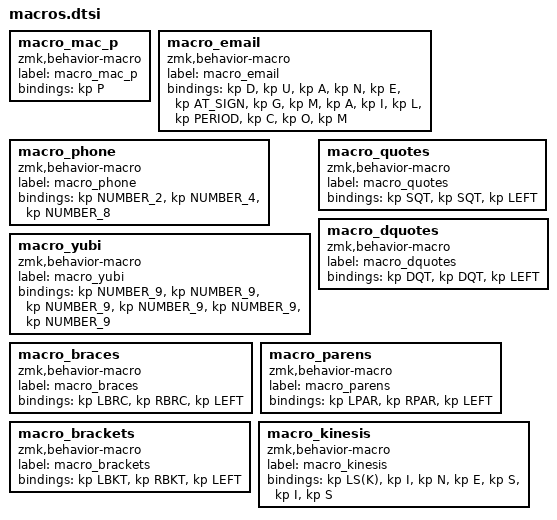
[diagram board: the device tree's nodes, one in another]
macro_mac_p: macro_mac_p{
compatible = "zmk,behavior-macro";
label = "macro_mac_p";
#binding-cells = <0>;
bindings = <&kp P>;
};
macro_email: macro_email{
compatible = "zmk,behavior-macro";
label = "macro_email";
#binding-cells = <0>;
bindings = <&kp D>, <&kp U>, <&kp A>, <&kp N>, <&kp E>, <&kp AT_SIGN>, <&kp G>, <&kp M>, <&kp A>, <&kp I>, <&kp L>, <&kp PERIOD>, <&kp C>, <&kp O>, <&kp M>;
};
macro_phone: macro_phone{
compatible = "zmk,behavior-macro";
label = "macro_phone";
#binding-cells = <0>;
bindings = <&kp NUMBER_2>, <&kp NUMBER_4>, <&kp NUMBER_8>;
};
macro_yubi: macro_yubi{
compatible = "zmk,behavior-macro";
label = "macro_yubi";
#binding-cells = <0>;
bindings = <&kp NUMBER_9>, <&kp NUMBER_9>, <&kp NUMBER_9>, <&kp NUMBER_9>, <&kp NUMBER_9>, <&kp NUMBER_9>;
};
macro_quotes: macro_quotes{
compatible = "zmk,behavior-macro";
label = "macro_quotes";
#binding-cells = <0>;
bindings = <&kp SQT>, <&kp SQT>, <&kp LEFT>;
};
macro_dquotes: macro_dquotes{
compatible = "zmk,behavior-macro";
label = "macro_dquotes";
#binding-cells = <0>;
bindings = <&kp DQT>, <&kp DQT>, <&kp LEFT>;
};
macro_braces: macro_braces{
compatible = "zmk,behavior-macro";
label = "macro_braces";
#binding-cells = <0>;
bindings = <&kp LBRC>, <&kp RBRC>, <&kp LEFT>;
};
macro_parens: macro_parens{
compatible = "zmk,behavior-macro";
label = "macro_parens";
#binding-cells = <0>;
bindings = <&kp LPAR>, <&kp RPAR>, <&kp LEFT>;
};
macro_brackets: macro_brackets{
compatible = "zmk,behavior-macro";
label = "macro_brackets";
#binding-cells = <0>;
bindings = <&kp LBKT>, <&kp RBKT>, <&kp LEFT>;
};
macro_kinesis: macro_kinesis{
compatible = "zmk,behavior-macro";
label = "macro_kinesis";
#binding-cells = <0>;
bindings = <&kp LS(K)>, <&kp I>, <&kp N>, <&kp E>, <&kp S>, <&kp I>, <&kp S>;
};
